# STM32F745IEK6 register map
File version: 1.0
Registers are 32-bit, access not given, reset 0x0 unless marked. A register's access mark holds for its fields unless they carry their own. Offsets are from the block's base; [hi:lo] are bit positions; {n}, {i} and the like mark numbered series; 'fields as' and 'values as' point back to an identical list.

## ETH
Base 0x40028000
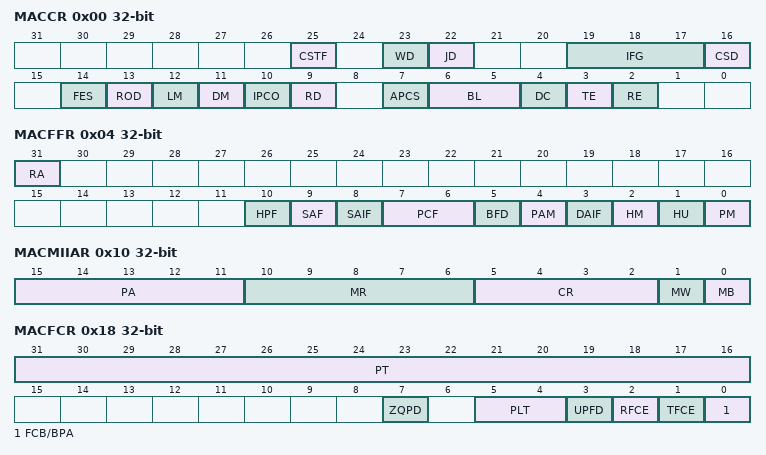
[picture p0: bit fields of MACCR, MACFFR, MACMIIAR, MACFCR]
0x00 MACCR
  [25] CSTF, [23] WD, [22] JD, [19:17] IFG, [16] CSD, [14] FES, [13] ROD, [12] LM, [11] DM, [10] IPCO, [9] RD, [7] APCS, [6:5] BL, [4] DC, [3] TE, [2] RE
0x04 MACFFR
  [31] RA, [10] HPF, [9] SAF, [8] SAIF, [7:6] PCF, [5] BFD, [4] PAM, [3] DAIF, [2] HM, [1] HU, [0] PM
0x08 MACHTHR
  [31:0] HTH
0x0C MACHTLR
  [31:0] HTL
0x10 MACMIIAR
  [15:11] PA, [10:6] MR, [5:2] CR, [1] MW, [0] MB
0x14 MACMIIDR
  [15:0] MD
0x18 MACFCR
  [31:16] PT, [7] ZQPD, [5:4] PLT, [3] UPFD, [2] RFCE, [1] TFCE, [0] FCB/BPA
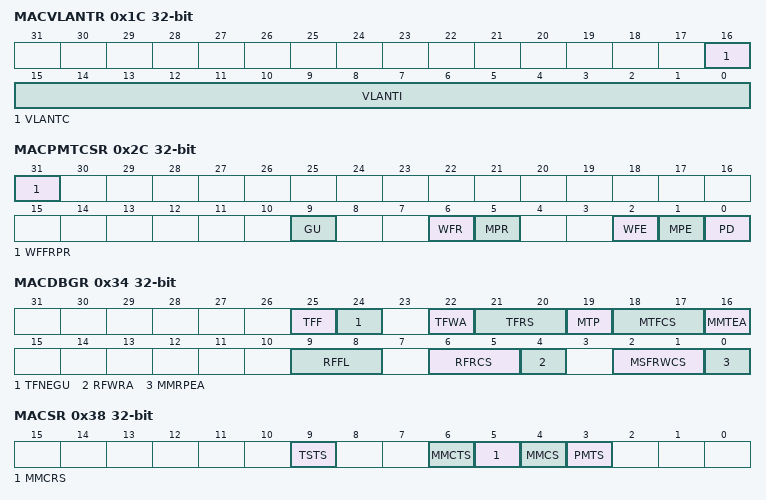
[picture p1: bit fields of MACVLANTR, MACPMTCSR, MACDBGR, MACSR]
0x1C MACVLANTR
  [16] VLANTC, [15:0] VLANTI
0x28 MACRWUFFR
  [31:0] FRAME_FILTER_REG
0x2C MACPMTCSR
  [31] WFFRPR, [9] GU, [6] WFR, [5] MPR, [2] WFE, [1] MPE, [0] PD
0x34 MACDBGR
  [25] TFF, [24] TFNEGU, [22] TFWA, [21:20] TFRS, [19] MTP, [18:17] MTFCS, [16] MMTEA, [9:8] RFFL, [6:5] RFRCS, [4] RFWRA, [2:1] MSFRWCS, [0] MMRPEA
0x38 MACSR
  [9] TSTS, [6] MMCTS, [5] MMCRS, [4] MMCS, [3] PMTS
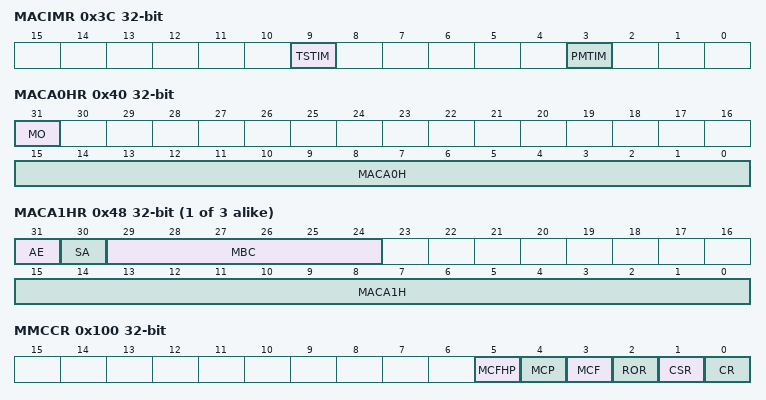
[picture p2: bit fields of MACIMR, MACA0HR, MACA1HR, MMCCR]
0x3C MACIMR
  [9] TSTIM, [3] PMTIM
0x40 MACA0HR
  [31] MO, [15:0] MACA0H
{0x44+8i} MACA{i}LR (i=0..3)
  [31:0] MACA{i}L
{0x40+8i} MACA{i}HR (i=1..3)
  [31] AE, [30] SA, [29:24] MBC, [15:0] MACA{i}H
0x100 MMCCR
  [5] MCFHP, [4] MCP, [3] MCF, [2] ROR, [1] CSR, [0] CR
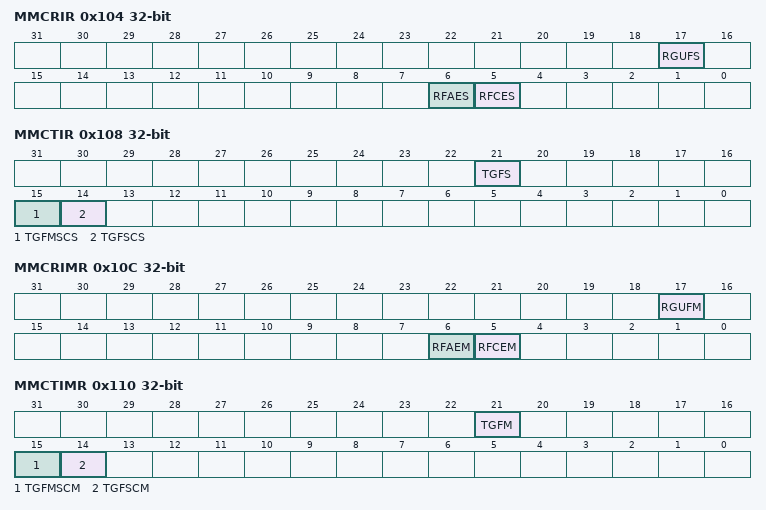
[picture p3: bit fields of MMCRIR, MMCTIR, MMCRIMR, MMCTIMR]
0x104 MMCRIR
  [17] RGUFS, [6] RFAES, [5] RFCES
0x108 MMCTIR
  [21] TGFS, [15] TGFMSCS, [14] TGFSCS
0x10C MMCRIMR
  [17] RGUFM, [6] RFAEM, [5] RFCEM
0x110 MMCTIMR
  [21] TGFM, [15] TGFMSCM, [14] TGFSCM
0x14C MMCTGFSCCR
  [31:0] TGFSCC
0x150 MMCTGFMSCCR
  [31:0] TGFMSCC
0x168 MMCTGFCR
  [31:0] TGFC
0x194 MMCRFCECR
  [31:0] RFCEC
0x198 MMCRFAECR
  [31:0] RFAEC
0x1C4 MMCRGUFCR
  [31:0] RGUFC
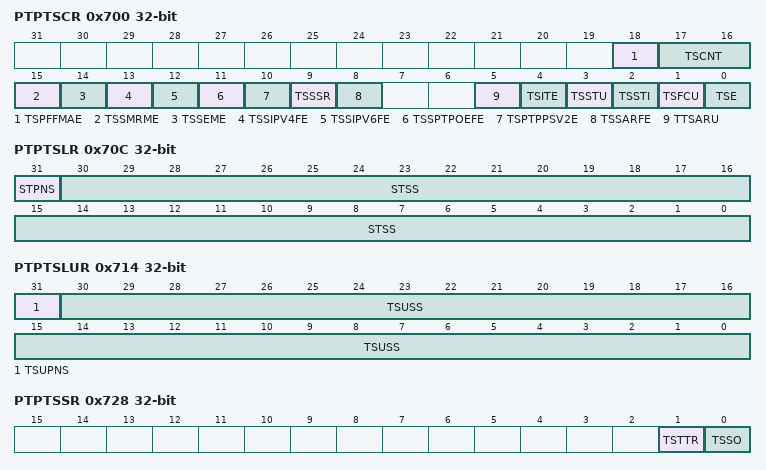
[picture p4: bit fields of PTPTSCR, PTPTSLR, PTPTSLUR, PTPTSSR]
0x700 PTPTSCR
  [18] TSPFFMAE, [17:16] TSCNT, [15] TSSMRME, [14] TSSEME, [13] TSSIPV4FE, [12] TSSIPV6FE, [11] TSSPTPOEFE, [10] TSPTPPSV2E, [9] TSSSR, [8] TSSARFE, [5] TTSARU, [4] TSITE, [3] TSSTU, [2] TSSTI, [1] TSFCU, [0] TSE
0x704 PTPSSIR
  [7:0] STSSI
0x708 PTPTSHR
  [31:0] STS
0x70C PTPTSLR
  [31] STPNS, [30:0] STSS
0x710 PTPTSHUR
  [31:0] TSUS
0x714 PTPTSLUR
  [31] TSUPNS, [30:0] TSUSS
0x718 PTPTSAR
  [31:0] TSA
0x71C PTPTTHR
  [31:0] TTSH
0x720 PTPTTLR
  [31:0] TTSL
0x728 PTPTSSR
  [1] TSTTR, [0] TSSO
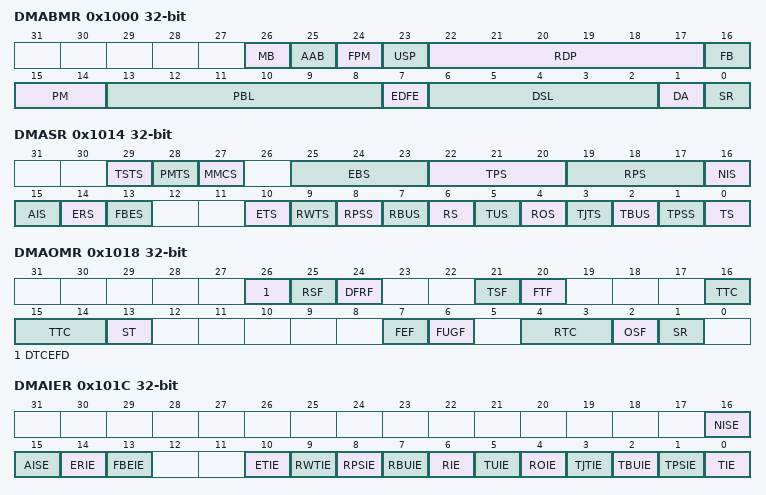
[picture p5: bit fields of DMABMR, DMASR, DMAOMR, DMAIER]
0x1000 DMABMR
  [26] MB, [25] AAB, [24] FPM, [23] USP, [22:17] RDP, [16] FB, [15:14] PM, [13:8] PBL, [7] EDFE, [6:2] DSL, [1] DA, [0] SR
0x1004 DMATPDR
  [31:0] TPD
0x1008 DMARPDR
  [31:0] RPD
0x100C DMARDLAR
  [31:0] SRL
0x1010 DMATDLAR
  [31:0] STL
0x1014 DMASR
  [29] TSTS, [28] PMTS, [27] MMCS, [25:23] EBS, [22:20] TPS, [19:17] RPS, [16] NIS, [15] AIS, [14] ERS, [13] FBES, [10] ETS, [9] RWTS, [8] RPSS, [7] RBUS, [6] RS, [5] TUS, [4] ROS, [3] TJTS, [2] TBUS, [1] TPSS, [0] TS
0x1018 DMAOMR
  [26] DTCEFD, [25] RSF, [24] DFRF, [21] TSF, [20] FTF, [16:14] TTC, [13] ST, [7] FEF, [6] FUGF, [4:3] RTC, [2] OSF, [1] SR
0x101C DMAIER
  [16] NISE, [15] AISE, [14] ERIE, [13] FBEIE, [10] ETIE, [9] RWTIE, [8] RPSIE, [7] RBUIE, [6] RIE, [5] TUIE, [4] ROIE, [3] TJTIE, [2] TBUIE, [1] TPSIE, [0] TIE
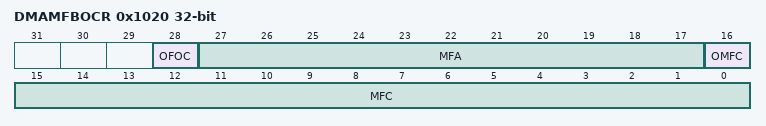
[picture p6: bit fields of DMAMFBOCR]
0x1020 DMAMFBOCR
  [28] OFOC, [27:17] MFA, [16] OMFC, [15:0] MFC
0x1024 DMARSWTR
  [7:0] RSWTC
0x1048 DMACHTDR
  [31:0] HTDAP
0x104C DMACHRDR
  [31:0] HRDAP
0x1050 DMACHTBAR
  [31:0] HTBAP
0x1054 DMACHRBAR
  [31:0] HRBAP

## DCMI
Base 0x50050000
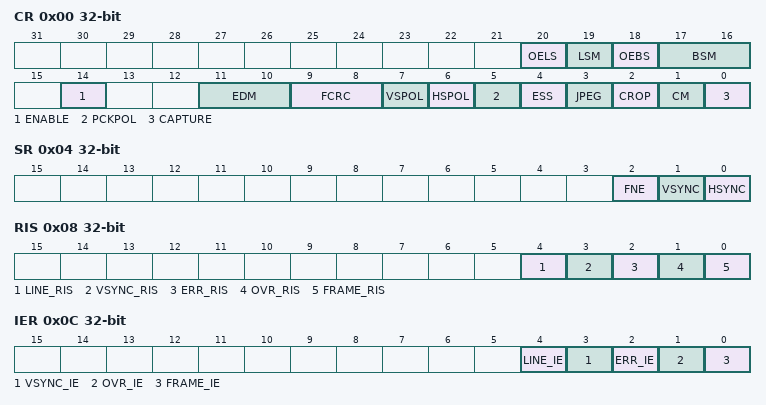
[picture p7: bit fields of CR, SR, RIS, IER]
0x00 CR
  [20] OELS, [19] LSM, [18] OEBS, [17:16] BSM, [14] ENABLE, [11:10] EDM, [9:8] FCRC, [7] VSPOL, [6] HSPOL, [5] PCKPOL, [4] ESS, [3] JPEG, [2] CROP, [1] CM, [0] CAPTURE
0x04 SR
  [2] FNE, [1] VSYNC, [0] HSYNC
0x08 RIS
  [4] LINE_RIS, [3] VSYNC_RIS, [2] ERR_RIS, [1] OVR_RIS, [0] FRAME_RIS
0x0C IER
  [4] LINE_IE, [3] VSYNC_IE, [2] ERR_IE, [1] OVR_IE, [0] FRAME_IE
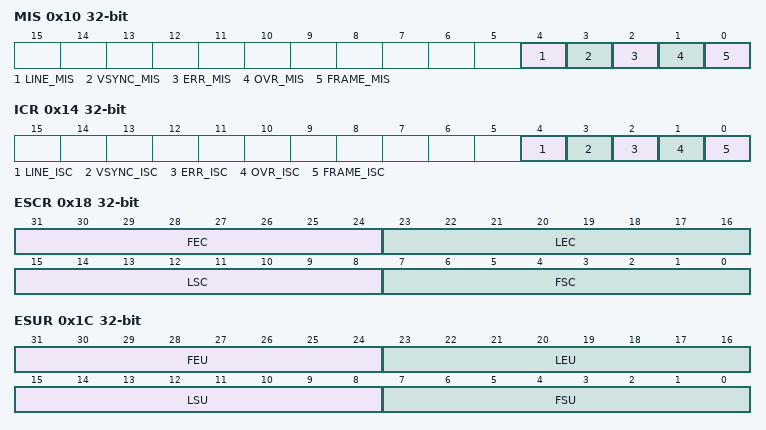
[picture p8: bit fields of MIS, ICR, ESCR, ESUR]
0x10 MIS
  [4] LINE_MIS, [3] VSYNC_MIS, [2] ERR_MIS, [1] OVR_MIS, [0] FRAME_MIS
0x14 ICR
  [4] LINE_ISC, [3] VSYNC_ISC, [2] ERR_ISC, [1] OVR_ISC, [0] FRAME_ISC
0x18 ESCR
  [31:24] FEC, [23:16] LEC, [15:8] LSC, [7:0] FSC
0x1C ESUR
  [31:24] FEU, [23:16] LEU, [15:8] LSU, [7:0] FSU
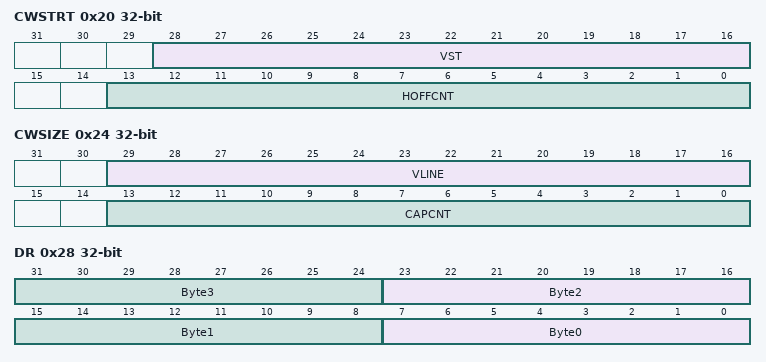
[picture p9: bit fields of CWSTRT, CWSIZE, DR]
0x20 CWSTRT
  [28:16] VST, [13:0] HOFFCNT
0x24 CWSIZE
  [29:16] VLINE, [13:0] CAPCNT
0x28 DR
  [8n+7:8n] Byte{n} (n=0..3)

## CRYP
Base 0x50060000
0x00 CR
  [17:16] GCM_CCMPH, [15] CRYPEN, [14] FFLUSH, [9:8] KEYSIZE, [7:6] DATATYPE, [19:3] ALGOMODE, [2] ALGODIR
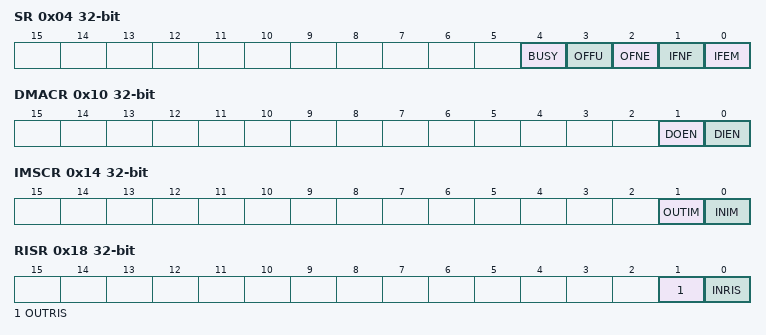
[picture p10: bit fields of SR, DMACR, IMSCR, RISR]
0x04 SR
  [4] BUSY, [3] OFFU, [2] OFNE, [1] IFNF, [0] IFEM
0x08 DIN
  [31:0] DATAIN
0x0C DOUT
  [31:0] DATAOUT
0x10 DMACR
  [1] DOEN, [0] DIEN
0x14 IMSCR
  [1] OUTIM, [0] INIM
0x18 RISR
  [1] OUTRIS, [0] INRIS
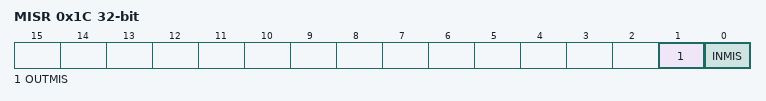
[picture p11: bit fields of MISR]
0x1C MISR
  [1] OUTMIS, [0] INMIS
0x20 K0LR
  [31:0] CRYP_K0LR
0x24 K0RR
  [31:0] CRYP_K0RR
0x38 K3LR
  [31:0] CRYP_K3LR
0x3C K3RR
  [31:0] CRYP_K3RR
0x40 IV0LR
  [31:0] CRYP_IV0LR
0x44 IV0RR
  [31:0] CRYP_IV0RR
0x48 IV1LR
  [31:0] CRYP_IV1LR
0x4C IV1RR
  [31:0] CRYP_IV1RR

## HASH
Base 0x50060400
0x00 CR
  [16] LKEY, [13] MDMAT, [12] DINNE, [11:8] NBW, [18:7] ALGO, [6] MODE, [5:4] DATATYPE, [3] DMAE, [2] INIT
0x04 DIN
  [31:0] DATAIN
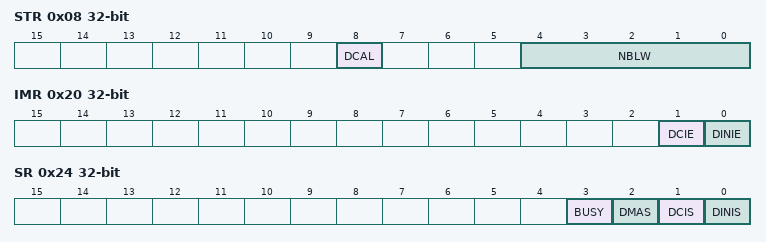
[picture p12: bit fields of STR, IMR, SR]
0x08 STR
  [8] DCAL, [4:0] NBLW
0x20 IMR
  [1] DCIE, [0] DINIE
0x24 SR
  [3] BUSY, [2] DMAS, [1] DCIS, [0] DINIS
0xF8 CSR0
0xFC CSR1
0x1CC CSR53
{0x310+4i} HR{i} (i=0..7)
  [31:0] H{i}

## RNG
Base 0x50060800
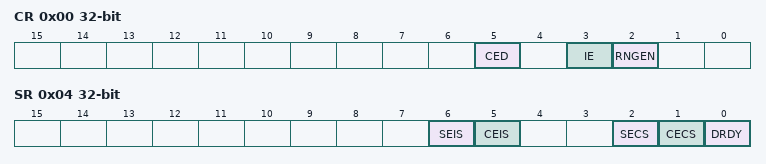
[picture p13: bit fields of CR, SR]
0x00 CR
  [5] CED, [3] IE, [2] RNGEN
0x04 SR
  [6] SEIS, [5] CEIS, [2] SECS, [1] CECS, [0] DRDY
0x08 DR
  [31:0] RNDATA

## FMC
Base 0xA0000000
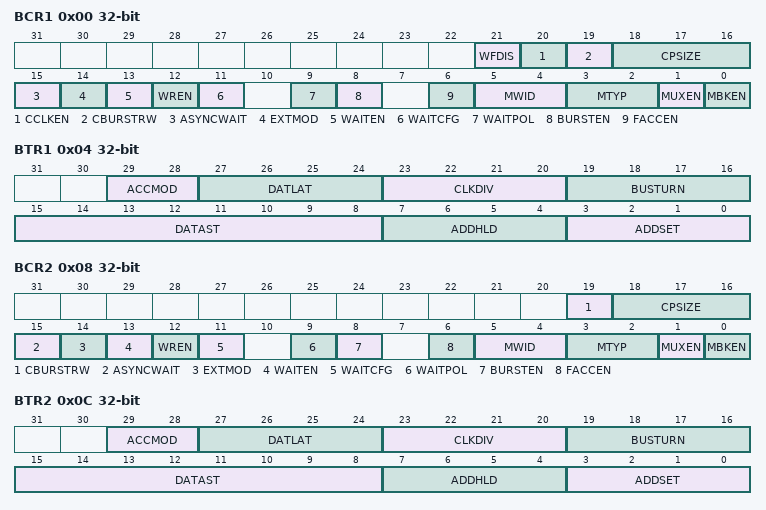
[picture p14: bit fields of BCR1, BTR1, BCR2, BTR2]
0x00 BCR1
  [21] WFDIS, [20] CCLKEN, [19] CBURSTRW, [18:16] CPSIZE, [15] ASYNCWAIT, [14] EXTMOD, [13] WAITEN, [12] WREN, [11] WAITCFG, [9] WAITPOL, [8] BURSTEN, [6] FACCEN, [5:4] MWID, [3:2] MTYP, [1] MUXEN, [0] MBKEN
0x04 BTR1
  [29:28] ACCMOD, [27:24] DATLAT, [23:20] CLKDIV, [19:16] BUSTURN, [15:8] DATAST, [7:4] ADDHLD, [3:0] ADDSET
0x08 BCR2
  [19] CBURSTRW, [18:16] CPSIZE, [15] ASYNCWAIT, [14] EXTMOD, [13] WAITEN, [12] WREN, [11] WAITCFG, [9] WAITPOL, [8] BURSTEN, [6] FACCEN, [5:4] MWID, [3:2] MTYP, [1] MUXEN, [0] MBKEN
0x0C BTR2
  fields as BTR1
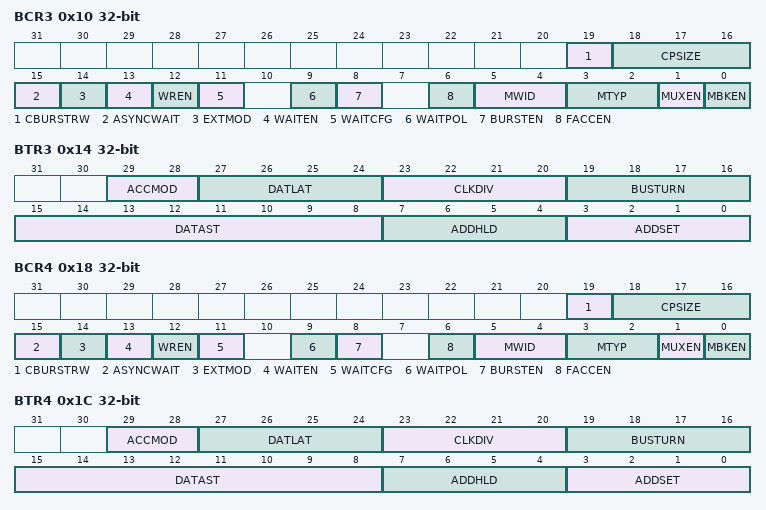
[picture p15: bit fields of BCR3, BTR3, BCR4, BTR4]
0x10 BCR3
  fields as BCR2
0x14 BTR3
  fields as BTR1
0x18 BCR4
  fields as BCR2
0x1C BTR4
  fields as BTR1
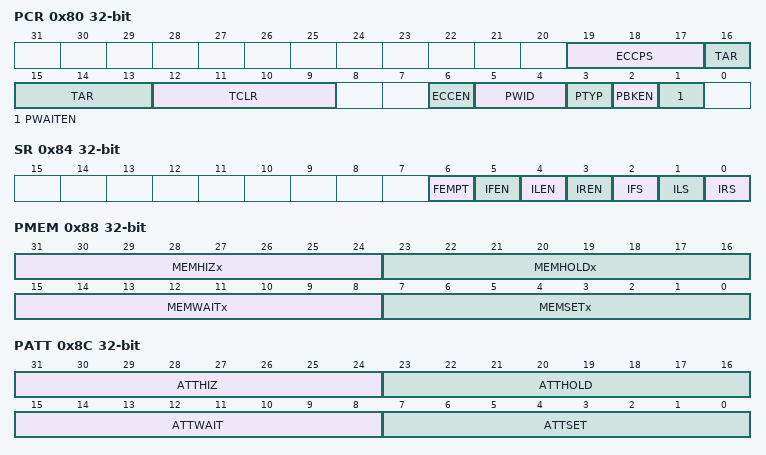
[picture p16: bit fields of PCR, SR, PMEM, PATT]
0x80 PCR
  [19:17] ECCPS, [16:13] TAR, [12:9] TCLR, [6] ECCEN, [5:4] PWID, [3] PTYP, [2] PBKEN, [1] PWAITEN
0x84 SR
  [6] FEMPT, [5] IFEN, [4] ILEN, [3] IREN, [2] IFS, [1] ILS, [0] IRS
0x88 PMEM
  [31:24] MEMHIZx, [23:16] MEMHOLDx, [15:8] MEMWAITx, [7:0] MEMSETx
0x8C PATT
  [31:24] ATTHIZ, [23:16] ATTHOLD, [15:8] ATTWAIT, [7:0] ATTSET
0x94 ECCR
  [31:0] ECCx
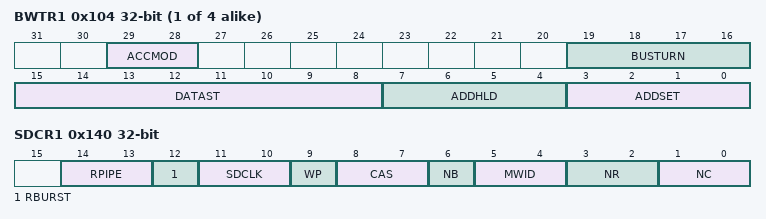
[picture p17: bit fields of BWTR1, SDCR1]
{0xFC+8i} BWTR{i} (i=1..4)
  [29:28] ACCMOD, [19:16] BUSTURN, [15:8] DATAST, [7:4] ADDHLD, [3:0] ADDSET
0x140 SDCR1
  [14:13] RPIPE, [12] RBURST, [11:10] SDCLK, [9] WP, [8:7] CAS, [6] NB, [5:4] MWID, [3:2] NR, [1:0] NC
0x144 SDCR2
  [12] RBURST, [11:10] SDCLK, [9] WP, [8:7] CAS, [6] NB, [5:4] MWID, [3:2] NR, [1:0] NC
0x148 SDTR1
  [27:24] TRCD, [23:20] TRP, [19:16] TWR, [15:12] TRC, [11:8] TRAS, [7:4] TXSR, [3:0] TMRD
0x14C SDTR2
  fields as SDTR1
0x150 SDCMR
  [21:9] MRD, [8:5] NRFS, [4] CTB1, [3] CTB2, [2:0] MODE
0x154 SDRTR
  [14] REIE, [13:1] COUNT, [0] CRE
0x158 SDSR
  [5] BUSY, [4:3] MODES2, [2:1] MODES1

## QSPICR
Base 0xA0001000
0x00 CR
  [31:24] PRESCALER, [23] PMM, [22] APMS, [20] TOIE, [19] SMIE, [18] FTIE, [17] TCIE, [16] TEIE, [12:8] FTHRES, [7] FSEL, [6] DFM, [4] SSHIFT, [3] TCEN, [2] DMAEN, [1] ABORT, [0] EN
0x04 DCR
  [20:16] FSIZE, [10:8] CSHT, [0] CKMODE
0x08 SR
  [14:8] FLEVEL, [5] BUSY, [4] TOF, [3] SMF, [2] FTF, [1] TCF, [0] TEF
0x0C FCR
  [4] CTOF, [3] CSMF, [1] CTCF, [0] CTEF
0x10 DLR
  [31:0] DL
0x14 CCR
  [31] DDRM, [30] DHHC, [28] SIOO, [27:26] FMODE, [25:24] DMODE, [22:18] DCYC, [17:16] ABSIZE, [15:14] ABMODE, [13:12] ADSIZE, [11:10] ADMODE, [9:8] IMODE, [7:0] INSTRUCTION
0x18 AR
  [31:0] ADDRESS
0x1C ABR
  [31:0] ALTERNATE
0x20 DR
  [31:0] DATA
0x24 PSMKR
  [31:0] MASK
0x28 PSMAR
  [31:0] MATCH
0x2C PIR
  [15:0] INTERVAL
0x30 LPTR
  [15:0] TIMEOUT
